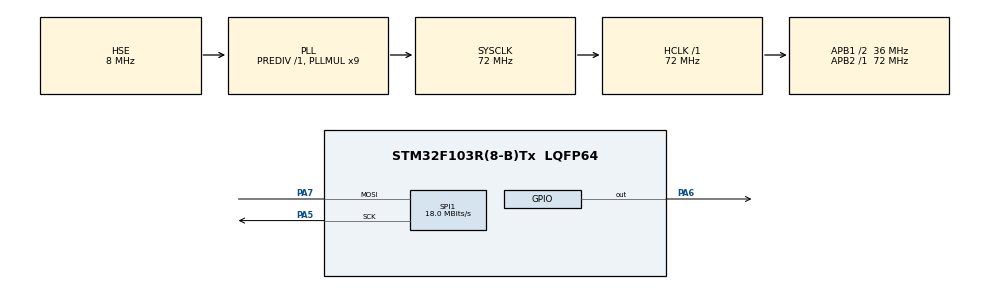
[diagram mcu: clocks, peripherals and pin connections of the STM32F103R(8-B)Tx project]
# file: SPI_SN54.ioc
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Mcu.Family=STM32F1
Mcu.Name=STM32F103R(8-B)Tx
Mcu.Package=LQFP64
NVIC.PriorityGroup=NVIC_PRIORITYGROUP_4
PA13.Mode=Serial_Wire
PA13.Signal=SYS_JTMS-SWDIO
PA14.Mode=Serial_Wire
PA14.Signal=SYS_JTCK-SWCLK
PA5.Mode=Simplex_Bidirectional_Master
PA5.Signal=SPI1_SCK
PA6.Signal=GPIO_Output
PA7.Mode=Simplex_Bidirectional_Master
PA7.Signal=SPI1_MOSI
PD0-OSC_IN.Mode=HSE-External-Oscillator
PD0-OSC_IN.Signal=RCC_OSC_IN
PD1-OSC_OUT.Mode=HSE-External-Oscillator
PD1-OSC_OUT.Signal=RCC_OSC_OUT
ProjectManager.HeapSize=0x200
ProjectManager.StackSize=0x400
ProjectManager.TargetToolchain=STM32CubeIDE
RCC.AHBFreq_Value=72000000
RCC.APB1CLKDivider=RCC_HCLK_DIV2
RCC.APB1Freq_Value=36000000
RCC.APB1TimFreq_Value=72000000
RCC.APB2Freq_Value=72000000
RCC.APB2TimFreq_Value=72000000
RCC.HCLKFreq_Value=72000000
RCC.PLLMUL=RCC_PLL_MUL9
RCC.PLLSourceVirtual=RCC_PLLSOURCE_HSE
RCC.SYSCLKFreq_VALUE=72000000
RCC.SYSCLKSource=RCC_SYSCLKSOURCE_PLLCLK
RCC.USBFreq_Value=72000000
SPI1.BaudRatePrescaler=SPI_BAUDRATEPRESCALER_4
SPI1.CalculateBaudRate=18.0 MBits/s
SPI1.Direction=SPI_DIRECTION_1LINE
SPI1.Mode=SPI_MODE_MASTER
SPI1.VirtualType=VM_MASTER
board=custom

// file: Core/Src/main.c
/* USER CODE BEGIN Header */
/**
  ******************************************************************************
  * @file           : main.c
  * @brief          : Main program body
  ******************************************************************************
  * @attention
  *
  * Copyright (c) 2022 STMicroelectronics.
  * All rights reserved.
  *
  * This software is licensed under terms that can be found in the LICENSE file
  * in the root directory of this software component.
  * If no LICENSE file comes with this software, it is provided AS-IS.
  *
  ******************************************************************************
  */
/* USER CODE END Header */
#include "main.h"
#include "spi.h"
#include "gpio.h"

/* USER CODE BEGIN PV */
/******************МАКРО ПОДСТАНОВКИ************************/
#define cs_set() HAL_GPIO_WritePin(GPIOA, GPIO_PIN_6, GPIO_PIN_RESET); //ВКЛЮЧЕНИЕ НОЖКИ CHIP SELECT
#define cs_reset() HAL_GPIO_WritePin(GPIOA, GPIO_PIN_6, GPIO_PIN_SET);
#define cs_strob() cs_reset() cs_set();
/******************МАКРО ПОДСТАНОВКИ************************/

/******************ИНИЦИАЛИЗАЦИЯ БУФЕРА*********************/
uint8_t buffer_stm [1];
uint8_t buffer_reg [1];
uint8_t i=0;
/******************ИНИЦИАЛИЗАЦИЯ БУФЕРА*********************/
/* USER CODE END PV */

void SystemClock_Config(void);

int main(void)
{

  /* MCU Configuration--------------------------------------------------------*/

  /* Reset of all peripherals, Initializes the Flash interface and the Systick. */
  HAL_Init();

  /* Configure the system clock */
  SystemClock_Config();

  /* Initialize all configured peripherals */
  MX_GPIO_Init();
  MX_SPI1_Init();
  /* USER CODE BEGIN 2 */
  buffer_stm [0] = 5;
  /*
  cs_set(); //ВЫБОР CHIP
  aTxBuffer [0] = 0x01; // ВНЕСЕНИЕ В ПЕРВЫЙ ЭЛЕМЕНТ БУФЕРА 1
  HAL_SPI_Transmit (&hspi1, (uint8_t*)aTxBuffer, 1, 5000);// ПЕРЕДАЧА БАЙТА
  cs_strob();
  HAL_Delay(1000);
  aTxBuffer [0] = 0xFF;
  HAL_SPI_Transmit (&hspi1, (uint8_t*)aTxBuffer, 1, 5000);// ПЕРЕДАЧА БАЙТА
  cs_strob();*/
  /* USER CODE END 2 */

  /* Infinite loop */
  while (1)
  {

    /* USER CODE BEGIN 3 */
/*************СОЗДАНИЕ СЧЁТЧИКА ЧТОБЫ ПРОВЕРИТЬ ВЕСЬ ОПЕРАТОР SWITCH*********/
	  for(i=0; i<=7;i++)
	  {
		  buffer_stm [0] = i;
	  }
/*************СОЗДАНИЕ СЧЁТЧИКА ЧТОБЫ ПРОВЕРИТЬ ВЕСЬ ОПЕРАТОР SWITCH*********/
	  switch (i)
	  {
	  case '1':
		  cs_set();
		  buffer_reg [0] = 0x03;//ТРЕТИЙ СВЕТОДИОД "КАНАЛ 3 ОК"
		  HAL_SPI_Transmit (&hspi1, (uint8_t*)buffer_reg, 1, 5000);// ПЕРЕДАЧА БАЙТА
		  cs_strob();
		  HAL_Delay(1000);
		  buffer_reg [0] = 0x04;//ЧЕТВЕРТЫЙ СВЕТОДИОД "КАНАЛ 4 НЕИСПР"
		  HAL_SPI_Transmit (&hspi1, (uint8_t*)buffer_reg, 1, 5000);// ПЕРЕДАЧА БАЙТА
		  cs_strob();
		  HAL_Delay(1000);
		  buffer_reg [0] = 0x05;//ПЯТЫЙ СВЕТОДИОД "КАНАЛ 5 НЕИСПР"
		  HAL_SPI_Transmit (&hspi1, (uint8_t*)buffer_reg, 1, 5000);// ПЕРЕДАЧА БАЙТА
		  cs_strob();
		  HAL_Delay(1000);
		  break;
	  case '2':
		  cs_set();
		  buffer_reg [0] = 0x02;//ВТОРОЙ СВЕТОДИОД "КАНАЛ 2 ОК"
		  HAL_SPI_Transmit (&hspi1, (uint8_t*)buffer_reg, 1, 5000);// ПЕРЕДАЧА БАЙТА
		  cs_strob();
		  HAL_Delay(1000);
		  buffer_reg [0] = 0x04;//ЧЕТВЕРТЫЙ СВЕТОДИОД "КАНАЛ 4 НЕИСПР"
		  HAL_SPI_Transmit (&hspi1, (uint8_t*)buffer_reg, 1, 5000);// ПЕРЕДАЧА БАЙТА
		  cs_strob();
		  HAL_Delay(1000);
		  buffer_reg [0] = 0x06;//ШЕСТОЙ СВЕТОДИОД "КАНАЛ 6 НЕИСПР"
		  HAL_SPI_Transmit (&hspi1, (uint8_t*)buffer_reg, 1, 5000);// ПЕРЕДАЧА БАЙТА
		  cs_strob();
		  HAL_Delay(1000);
		  break;
	  case'3':
		  cs_set();
		  buffer_reg [0] = 0x02;//ВТОРОЙ СВЕТОДИОД "КАНАЛ 2 ОК"
		  HAL_SPI_Transmit (&hspi1, (uint8_t*)buffer_reg, 1, 5000);// ПЕРЕДАЧА БАЙТА
		  cs_strob();
		  HAL_Delay(1000);
		  buffer_reg [0] = 0x03;// ТРЕТИЙ СВЕТОДИОД "КАНАЛ 3 ОК"
		  HAL_SPI_Transmit (&hspi1, (uint8_t*)buffer_reg, 1, 5000);// ПЕРЕДАЧА БАЙТА
		  cs_strob();
		  HAL_Delay(1000);
		  buffer_reg [0] = 0x04;//ЧЕТВЕРТЫЙ СВЕТОДИОД "КАНАЛ 4 НЕИСПР"
		  HAL_SPI_Transmit (&hspi1, (uint8_t*)buffer_reg, 1, 5000);// ПЕРЕДАЧА БАЙТА
		  cs_strob();
		  HAL_Delay(1000);
		  break;
	  case '4':
		 cs_set();
		 buffer_reg [0] = 0x03;// ТРЕТИЙ СВЕТОДИОД "КАНАЛ 3 ОК"
		 HAL_SPI_Transmit (&hspi1, (uint8_t*)buffer_reg, 1, 5000);// ПЕРЕДАЧА БАЙТА
		 cs_strob();
		 HAL_Delay(1000);
		 buffer_reg [0] = 0x05;//ПЯТЫЙ СВЕТОДИОД "КАНАЛ 5 НЕИСПР"
		 HAL_SPI_Transmit (&hspi1, (uint8_t*)buffer_reg, 1, 5000);// ПЕРЕДАЧА БАЙТА
		 cs_strob();
		 HAL_Delay(1000);
		 buffer_reg [0] = 0x06;//ШЕСТОЙ СВЕТОДИОД "КАНАЛ 6 НЕИСПР"
		 HAL_SPI_Transmit (&hspi1, (uint8_t*)buffer_reg, 1, 5000);// ПЕРЕДАЧА БАЙТА
		 cs_strob();
		 HAL_Delay(1000);
		 break;
	  case '5':
		  cs_set();
		  buffer_reg [0] = 0x01;//ПЕРВЫЙ СВЕТОДИОД "КАНАЛ 1 ОК"
		  HAL_SPI_Transmit (&hspi1, (uint8_t*)buffer_reg, 1, 5000);// ПЕРЕДАЧА БАЙТА
		  cs_strob();
		  HAL_Delay(1000);
		  buffer_reg [0] = 0x03;// ТРЕТИЙ СВЕТОДИОД "КАНАЛ 3 ОК"
		  HAL_SPI_Transmit (&hspi1, (uint8_t*)buffer_reg, 1, 5000);// ПЕРЕДАЧА БАЙТА
		  cs_strob();
		  HAL_Delay(1000);
		  buffer_reg [0] = 0x05;//ПЯТЫЙ СВЕТОДИОД "КАНАЛ 5 НЕИСПР"
		  HAL_SPI_Transmit (&hspi1, (uint8_t*)buffer_reg, 1, 5000);// ПЕРЕДАЧА БАЙТА
		  cs_strob();
		  HAL_Delay(1000);
		  break;
	  case '6':
		  cs_set();
		  buffer_reg [0] = 0x01;//ПЕРВЫЙ СВЕТОДИОД "КАНАЛ 1 ОК"
		  HAL_SPI_Transmit (&hspi1, (uint8_t*)buffer_reg, 1, 5000);// ПЕРЕДАЧА БАЙТА
		  cs_strob();
		  HAL_Delay(1000);
		  buffer_reg [0] = 0x02;//ВТОРОЙ СВЕТОДИОД "КАНАЛ 2 ОК"
		  HAL_SPI_Transmit (&hspi1, (uint8_t*)buffer_reg, 1, 5000);// ПЕРЕДАЧА БАЙТА
		  cs_strob();
		  HAL_Delay(1000);
		  buffer_reg [0] = 0x06;//ШЕСТОЙ СВЕТОДИОД "КАНАЛ 6 НЕИСПР"
		  HAL_SPI_Transmit (&hspi1, (uint8_t*)buffer_reg, 1, 5000);// ПЕРЕДАЧА БАЙТА
		  cs_strob();
		  HAL_Delay(1000);
		  break;
	  case '7':
		  cs_set();
		  buffer_reg [0] = 0x01;//ПЕРВЫЙ СВЕТОДИОД "КАНАЛ 1 ОК"
		  HAL_SPI_Transmit (&hspi1, (uint8_t*)buffer_reg, 1, 5000);// ПЕРЕДАЧА БАЙТА
		  cs_strob();
		  HAL_Delay(1000);
		  buffer_reg [0] = 0x02;//ВТОРОЙ СВЕТОДИОД "КАНАЛ 2 ОК"
		  HAL_SPI_Transmit (&hspi1, (uint8_t*)buffer_reg, 1, 5000);// ПЕРЕДАЧА БАЙТА
		  cs_strob();
		  HAL_Delay(1000);
		  buffer_reg [0] = 0x03;// ТРЕТИЙ СВЕТОДИОД "КАНАЛ 3 ОК"
		  HAL_SPI_Transmit (&hspi1, (uint8_t*)buffer_reg, 1, 5000);// ПЕРЕДАЧА БАЙТА
		  cs_strob();
		  HAL_Delay(1000);
		  break;
	  }
  }
  /* USER CODE END 3 */
}

void SystemClock_Config(void)
{
  RCC_OscInitTypeDef RCC_OscInitStruct = {0};
  RCC_ClkInitTypeDef RCC_ClkInitStruct = {0};

  /** Initializes the RCC Oscillators according to the specified parameters
  * in the RCC_OscInitTypeDef structure.
  */
  RCC_OscInitStruct.OscillatorType = RCC_OSCILLATORTYPE_HSE;
  RCC_OscInitStruct.HSEState = RCC_HSE_ON;
  RCC_OscInitStruct.HSEPredivValue = RCC_HSE_PREDIV_DIV1;
  RCC_OscInitStruct.HSIState = RCC_HSI_ON;
  RCC_OscInitStruct.PLL.PLLState = RCC_PLL_ON;
  RCC_OscInitStruct.PLL.PLLSource = RCC_PLLSOURCE_HSE;
  RCC_OscInitStruct.PLL.PLLMUL = RCC_PLL_MUL9;
  if (HAL_RCC_OscConfig(&RCC_OscInitStruct) != HAL_OK)
  {
    Error_Handler();
  }

  /** Initializes the CPU, AHB and APB buses clocks
  */
  RCC_ClkInitStruct.ClockType = RCC_CLOCKTYPE_HCLK|RCC_CLOCKTYPE_SYSCLK
                              |RCC_CLOCKTYPE_PCLK1|RCC_CLOCKTYPE_PCLK2;
  RCC_ClkInitStruct.SYSCLKSource = RCC_SYSCLKSOURCE_PLLCLK;
  RCC_ClkInitStruct.AHBCLKDivider = RCC_SYSCLK_DIV1;
  RCC_ClkInitStruct.APB1CLKDivider = RCC_HCLK_DIV2;
  RCC_ClkInitStruct.APB2CLKDivider = RCC_HCLK_DIV1;

  if (HAL_RCC_ClockConfig(&RCC_ClkInitStruct, FLASH_LATENCY_2) != HAL_OK)
  {
    Error_Handler();
  }
}

void Error_Handler(void)
{
  __disable_irq();
  while (1)
  {
  }
}
